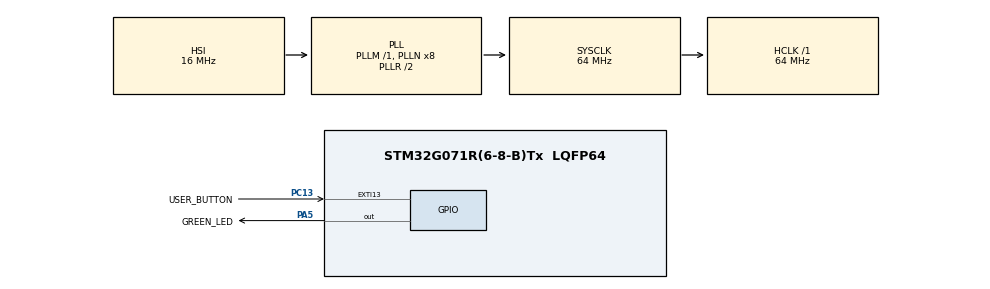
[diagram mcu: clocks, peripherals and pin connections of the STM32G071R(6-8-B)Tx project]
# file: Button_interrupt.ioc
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Mcu.Family=STM32G0
RCC.CortexFreq_Value=64000000
PC13.Signal=GPXTI13
PA14-BOOT0.Mode=Serial_Wire
RCC.EXTERNAL_CLOCK_VALUE=48000
PC13.GPIO_Label=USER_BUTTON
RCC.SYSCLKSource=RCC_SYSCLKSOURCE_PLLCLK
ProjectManager.StackSize=0x400
PA13.Signal=SYS_SWDIO
ProjectManager.TargetToolchain=STM32CubeIDE
RCC.HCLKFreq_Value=64000000
RCC.LSE_VALUE=32768
RCC.AHBFreq_Value=64000000
PA14-BOOT0.Signal=SYS_SWCLK
PA5.Signal=GPIO_Output
RCC.HSE_VALUE=8000000
board=custom
RCC.VCOOutputFreq_Value=128000000
RCC.ADCFreq_Value=64000000
VP_SYS_VS_DBSignals.Mode=DisableDeadBatterySignals
PA13.Mode=Serial_Wire
Mcu.Name=STM32G071R(6-8-B)Tx
RCC.SYSCLKFreq_VALUE=64000000
Mcu.Package=LQFP64
PA5.GPIO_Label=GREEN_LED
PC13.GPIO_ModeDefaultEXTI=GPIO_MODE_IT_FALLING
ProjectManager.HeapSize=0x200
RCC.HSI_VALUE=16000000
NVIC.EXTI4_15_IRQn=true\:1\:0\:true\:false\:true\:true\:true

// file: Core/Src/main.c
/* USER CODE BEGIN Header */
/**
  ******************************************************************************
  * @file           : main.c
  * @brief          : Main program body
  ******************************************************************************
  * @attention
  *
  * <h2><center>&copy; Copyright (c) 2021 STMicroelectronics.
  * All rights reserved.</center></h2>
  *
  * This software component is licensed by ST under BSD 3-Clause license,
  * the "License"; You may not use this file except in compliance with the
  * License. You may obtain a copy of the License at:
  *                        opensource.org/licenses/BSD-3-Clause
  *
  ******************************************************************************
  */
/* USER CODE END Header */
#include "main.h"

void SystemClock_Config(void);
static void MX_GPIO_Init(void);
/* USER CODE BEGIN PFP */
uint8_t modeSelection = 0;

/* USER CODE END PFP */

/* USER CODE BEGIN 0 */
void HAL_GPIO_EXTI_Falling_Callback(uint16_t GPIO_Pin)
{
  /* Prevent unused argument(s) compilation warning */
  UNUSED(GPIO_Pin);

  /* NOTE: This function should not be modified, when the callback is needed,
           the HAL_GPIO_EXTI_Falling_Callback could be implemented in the user file
   */
  if (GPIO_Pin == USER_BUTTON_Pin) {
	modeSelection++;

	if (modeSelection > 2) {
		modeSelection = 0;
	}
  }

}
/* USER CODE END 0 */

int main(void)
{

  /* MCU Configuration--------------------------------------------------------*/

  /* Reset of all peripherals, Initializes the Flash interface and the Systick. */
  HAL_Init();

  /* Configure the system clock */
  SystemClock_Config();

  /* Initialize all configured peripherals */
  MX_GPIO_Init();

  /* Infinite loop */
  while (1)
  {

    /* USER CODE BEGIN 3 */
	  if (modeSelection == 0) {
		HAL_GPIO_TogglePin(GREEN_LED_GPIO_Port, GREEN_LED_Pin);
		HAL_Delay(500);
	}
	  else if( modeSelection == 1){
		HAL_GPIO_WritePin(GREEN_LED_GPIO_Port, GREEN_LED_Pin, GPIO_PIN_RESET);
		HAL_Delay(300);
	}
	else if (modeSelection == 2){
		HAL_GPIO_WritePin(GREEN_LED_GPIO_Port, GREEN_LED_Pin, GPIO_PIN_SET);
		HAL_Delay(300);
	}

  }
  /* USER CODE END 3 */
}

void SystemClock_Config(void)
{
  RCC_OscInitTypeDef RCC_OscInitStruct = {0};
  RCC_ClkInitTypeDef RCC_ClkInitStruct = {0};

  /** Configure the main internal regulator output voltage
  */
  HAL_PWREx_ControlVoltageScaling(PWR_REGULATOR_VOLTAGE_SCALE1);
  /** Initializes the RCC Oscillators according to the specified parameters
  * in the RCC_OscInitTypeDef structure.
  */
  RCC_OscInitStruct.OscillatorType = RCC_OSCILLATORTYPE_HSI;
  RCC_OscInitStruct.HSIState = RCC_HSI_ON;
  RCC_OscInitStruct.HSIDiv = RCC_HSI_DIV1;
  RCC_OscInitStruct.HSICalibrationValue = RCC_HSICALIBRATION_DEFAULT;
  RCC_OscInitStruct.PLL.PLLState = RCC_PLL_ON;
  RCC_OscInitStruct.PLL.PLLSource = RCC_PLLSOURCE_HSI;
  RCC_OscInitStruct.PLL.PLLM = RCC_PLLM_DIV1;
  RCC_OscInitStruct.PLL.PLLN = 8;
  RCC_OscInitStruct.PLL.PLLP = RCC_PLLP_DIV2;
  RCC_OscInitStruct.PLL.PLLQ = RCC_PLLQ_DIV2;
  RCC_OscInitStruct.PLL.PLLR = RCC_PLLR_DIV2;
  if (HAL_RCC_OscConfig(&RCC_OscInitStruct) != HAL_OK)
  {
    Error_Handler();
  }
  /** Initializes the CPU, AHB and APB buses clocks
  */
  RCC_ClkInitStruct.ClockType = RCC_CLOCKTYPE_HCLK|RCC_CLOCKTYPE_SYSCLK
                              |RCC_CLOCKTYPE_PCLK1;
  RCC_ClkInitStruct.SYSCLKSource = RCC_SYSCLKSOURCE_PLLCLK;
  RCC_ClkInitStruct.AHBCLKDivider = RCC_SYSCLK_DIV1;
  RCC_ClkInitStruct.APB1CLKDivider = RCC_HCLK_DIV1;

  if (HAL_RCC_ClockConfig(&RCC_ClkInitStruct, FLASH_LATENCY_2) != HAL_OK)
  {
    Error_Handler();
  }
}

static void MX_GPIO_Init(void)
{
  GPIO_InitTypeDef GPIO_InitStruct = {0};

  /* GPIO Ports Clock Enable */
  __HAL_RCC_GPIOC_CLK_ENABLE();
  __HAL_RCC_GPIOA_CLK_ENABLE();

  /*Configure GPIO pin Output Level */
  HAL_GPIO_WritePin(GREEN_LED_GPIO_Port, GREEN_LED_Pin, GPIO_PIN_RESET);

  /*Configure GPIO pin : USER_BUTTON_Pin */
  GPIO_InitStruct.Pin = USER_BUTTON_Pin;
  GPIO_InitStruct.Mode = GPIO_MODE_IT_FALLING;
  GPIO_InitStruct.Pull = GPIO_NOPULL;
  HAL_GPIO_Init(USER_BUTTON_GPIO_Port, &GPIO_InitStruct);

  /*Configure GPIO pin : GREEN_LED_Pin */
  GPIO_InitStruct.Pin = GREEN_LED_Pin;
  GPIO_InitStruct.Mode = GPIO_MODE_OUTPUT_PP;
  GPIO_InitStruct.Pull = GPIO_NOPULL;
  GPIO_InitStruct.Speed = GPIO_SPEED_FREQ_LOW;
  HAL_GPIO_Init(GREEN_LED_GPIO_Port, &GPIO_InitStruct);

  /* EXTI interrupt init*/
  HAL_NVIC_SetPriority(EXTI4_15_IRQn, 1, 0);
  HAL_NVIC_EnableIRQ(EXTI4_15_IRQn);

}

void Error_Handler(void)
{
  __disable_irq();
  while (1)
  {
  }
}

/************************ (C) COPYRIGHT STMicroelectronics *****END OF FILE****/
